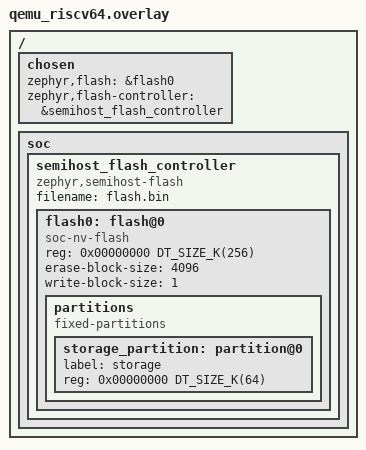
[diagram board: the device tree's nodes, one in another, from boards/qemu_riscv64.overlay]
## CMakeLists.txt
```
#
# Copyright (c) 2026 Analog Devices Inc.
#
# SPDX-License-Identifier: Apache-2.0
#

cmake_minimum_required(VERSION 3.20.0)
find_package(Zephyr REQUIRED HINTS $ENV{ZEPHYR_BASE})
project(flash_preload)

target_sources(app PRIVATE src/main.c)

if(CONFIG_FLASH_SEMIHOST)
  # Write to "flash.bin" in the build folder. This is used by the flash semihost driver to simulate flash memory.
  file(WRITE "${CMAKE_BINARY_DIR}/flash.bin" "flash_data")
endif()
```

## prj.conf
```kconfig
CONFIG_ZTEST=y
CONFIG_FLASH=y
```

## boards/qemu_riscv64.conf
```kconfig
# SPDX-License-Identifier: Apache-2.0
# Copyright (c) 2026 Analog Devices, Inc.

CONFIG_FLASH=y
CONFIG_FLASH_PAGE_LAYOUT=y
CONFIG_SEMIHOST=y
```

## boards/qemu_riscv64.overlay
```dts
/*
 * SPDX-License-Identifier: Apache-2.0
 * Copyright (c) 2026 Analog Devices, Inc.
 */

#include <mem.h>

/ {
	chosen {
		zephyr,flash = &flash0;
		zephyr,flash-controller = &semihost_flash_controller;
	};

	soc {
		semihost_flash_controller: semihost_flash_controller {
			compatible = "zephyr,semihost-flash";
			filename = "flash.bin";
			#address-cells = <1>;
			#size-cells = <1>;

			flash0: flash@0 {
				compatible = "soc-nv-flash";
				reg = <0x00000000 DT_SIZE_K(256)>;
				erase-block-size = <4096>;
				write-block-size = <1>;

				partitions {
					compatible = "fixed-partitions";
					#address-cells = <1>;
					#size-cells = <1>;

					storage_partition: partition@0 {
						label = "storage";
						reg = <0x00000000 DT_SIZE_K(64)>;
					};
				};
			};
		};
	};
};
```

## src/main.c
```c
/*
 * Copyright (c) 2026 Analog Devices Inc.
 *
 * SPDX-License-Identifier: Apache-2.0
 */

#include <zephyr/ztest.h>
#include <zephyr/drivers/flash.h>
#include <zephyr/device.h>
#include <zephyr/devicetree.h>
#include <zephyr/storage/flash_map.h>

#define MAGIC_STRING "flash_data"

#define TEST_AREA_OFFSET	PARTITION_OFFSET(storage_partition)
#define TEST_AREA_SIZE		PARTITION_SIZE(storage_partition)
#define TEST_AREA_MAX		(TEST_AREA_OFFSET + TEST_AREA_SIZE)
#define TEST_AREA_DEVICE	PARTITION_DEVICE(storage_partition)

static const struct device *const flash_dev = TEST_AREA_DEVICE;

ZTEST(flash_preload, test_preload_data)
{
	char word[sizeof(MAGIC_STRING)];
	int rc;

	rc = flash_read(flash_dev, TEST_AREA_OFFSET, &word, sizeof(word));
	zassert_equal(0, rc, "Failed to read flash");
	zassert_mem_equal(MAGIC_STRING, word, sizeof(MAGIC_STRING),
					  "Magic string not present in flash");
}

void *flash_preload_setup(void)
{
	zassert_true(device_is_ready(flash_dev), "flash device not ready");

	return NULL;
}

ZTEST_SUITE(flash_preload, NULL, flash_preload_setup, NULL, NULL, NULL);
```
